# RX64M_SSI_Pilot register map
File version: 1.0
RX64M_SSI_Pilot peripheral registers generated from iodefine.h (pilot).
Registers are 32-bit, read-write, reset 0x0 unless marked. A register's access mark holds for its fields unless they carry their own. Offsets are from the block's base; lines under a group give offsets from that group; [hi:lo] are bit positions; {n}, {i} and the like mark numbered series; 'fields as' and 'values as' point back to an identical list; <NAME> marks a mode.

## Memory map
0x0008A500 SSI0 size 0x24
0x0008A540 SSI1 size 0x24

## SSI0
Base 0x0008A500
Same registers: SSI1 0x0008A540
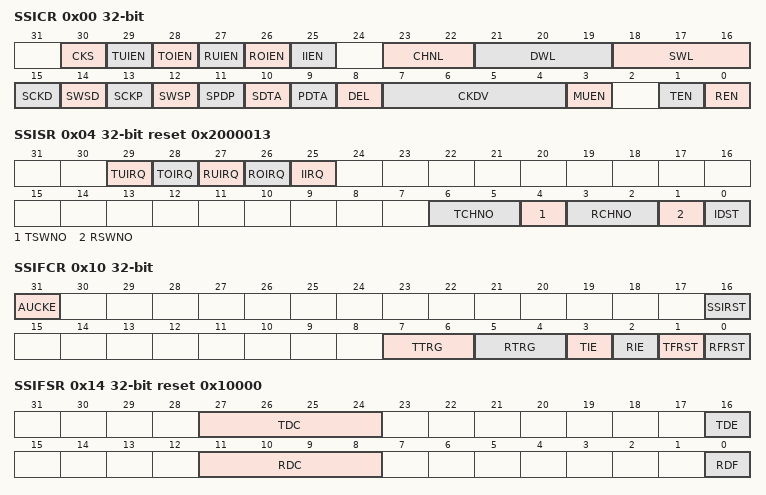
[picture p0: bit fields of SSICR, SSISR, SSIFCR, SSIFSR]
0x00 SSICR
  [30] CKS, [29] TUIEN, [28] TOIEN, [27] RUIEN, [26] ROIEN, [25] IIEN, [23:22] CHNL, [21:19] DWL, [18:16] SWL, [15] SCKD, [14] SWSD, [13] SCKP, [12] SWSP, [11] SPDP, [10] SDTA, [9] PDTA, [8] DEL, [7:4] CKDV, [3] MUEN, [1] TEN, [0] REN
0x04 SSISR reset 0x2000013
  [29] TUIRQ, [28] TOIRQ, [27] RUIRQ, [26] ROIRQ, [25] IIRQ, [6:5] TCHNO, [4] TSWNO, [3:2] RCHNO, [1] RSWNO, [0] IDST
0x10 SSIFCR
  [31] AUCKE, [16] SSIRST, [7:6] TTRG, [5:4] RTRG, [3] TIE, [2] RIE, [1] TFRST, [0] RFRST
0x14 SSIFSR reset 0x10000
  [27:24] TDC, [16] TDE, [11:8] RDC, [0] RDF
0x18 SSIFTDR wo reset not defined
0x1C SSIFRDR ro reset not defined
0x20 SSITDMR
  [8] CONT
